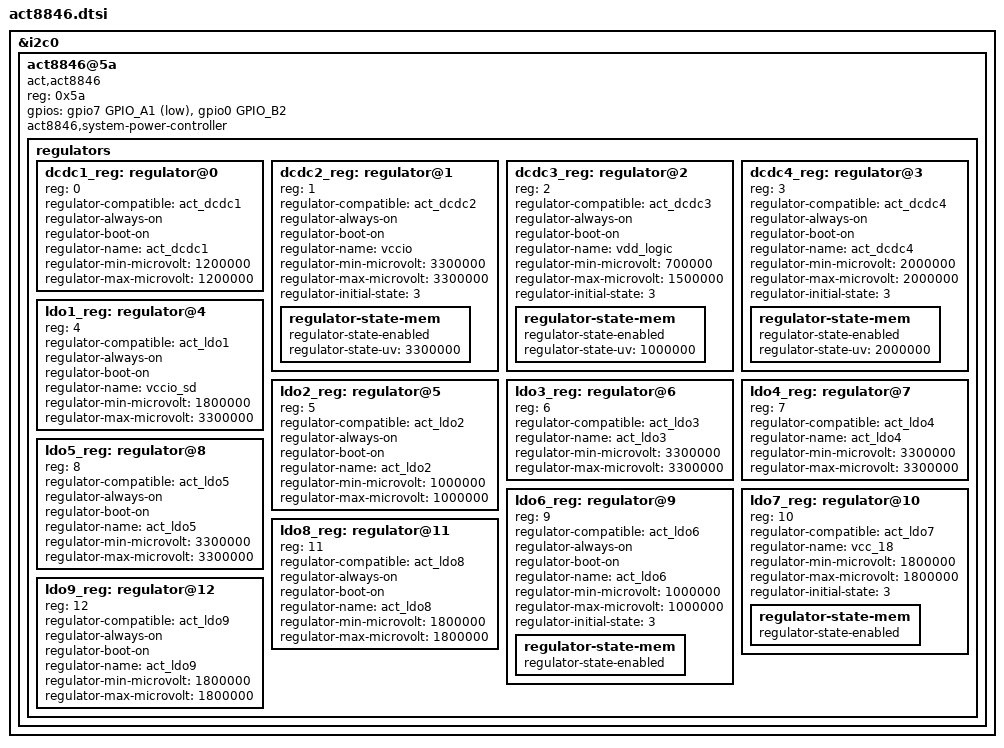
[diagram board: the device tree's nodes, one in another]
&i2c0 {
	act8846@5a {
		reg = <0x5a>;
		status = "okay";
		compatible = "act,act8846";
		gpios =<&gpio7 GPIO_A1 GPIO_ACTIVE_LOW>,<&gpio0 GPIO_B2 GPIO_ACTIVE_HIGH>;
		act8846,system-power-controller;
		regulators {
		#address-cells = <1>;
		#size-cells = <0>;

dcdc1_reg: regulator@0{
			   reg = <0>;
			   regulator-compatible= "act_dcdc1";
			   regulator-always-on;
			   regulator-boot-on;
			   regulator-name= "act_dcdc1";
			   regulator-min-microvolt = <1200000>;
			   regulator-max-microvolt = <1200000>;
		   };

dcdc2_reg: regulator@1 {
			   reg = <1>;
			   regulator-compatible = "act_dcdc2";
			   regulator-always-on;
			   regulator-boot-on;
			   regulator-name= "vccio";
			   regulator-min-microvolt = <3300000>;
			   regulator-max-microvolt = <3300000>;
			   regulator-initial-state = <3>;
			   regulator-state-mem {
				   regulator-state-enabled;
				   regulator-state-uv = <3300000>;
			   };
		   };

dcdc3_reg: regulator@2 {
			   reg = <2>;
			   regulator-compatible = "act_dcdc3";
			   regulator-always-on;
			   regulator-boot-on;
			   regulator-name= "vdd_logic";
			   regulator-min-microvolt = <700000>;
			   regulator-max-microvolt = <1500000>;
			   regulator-initial-state = <3>;
			   regulator-state-mem {
				   regulator-state-enabled;
				   regulator-state-uv = <1000000>;
			   };
		   };

dcdc4_reg: regulator@3 {
			   reg = <3>;
			   regulator-compatible = "act_dcdc4";
			   regulator-always-on;
			   regulator-boot-on;
			   regulator-name= "act_dcdc4";
			   regulator-min-microvolt = <2000000>;
			   regulator-max-microvolt = <2000000>;
			   regulator-initial-state = <3>;
			   regulator-state-mem {
				   regulator-state-enabled;
				   regulator-state-uv = <2000000>;
			   };
		   };

ldo1_reg: regulator@4 {
			  reg = <4>;
			  regulator-compatible= "act_ldo1";
			  regulator-always-on;
			  regulator-boot-on;
			  regulator-name= "vccio_sd";
			  regulator-min-microvolt = <1800000>;
			  regulator-max-microvolt = <3300000>;
		  };

ldo2_reg: regulator@5 {
			  reg = <5>;
			  regulator-compatible = "act_ldo2";
			  regulator-always-on;
			  regulator-boot-on;
			  regulator-name= "act_ldo2";
			  regulator-min-microvolt = <1000000>;
			  regulator-max-microvolt = <1000000>;
		  };

ldo3_reg: regulator@6 {
			  reg = <6>;
			  regulator-compatible = "act_ldo3";
			  /* regulator-always-on; */
			  /* regulator-boot-on; */
			  regulator-name= "act_ldo3";
			  regulator-min-microvolt = <3300000>;
			  regulator-max-microvolt = <3300000>;
		  };

ldo4_reg:regulator@7 {
			 reg = <7>;
			 regulator-compatible = "act_ldo4";
			 /* regulator-always-on; */
			 /*  regulator-boot-on; */
			 regulator-name= "act_ldo4";
			 regulator-min-microvolt = <3300000>;
			 regulator-max-microvolt = <3300000>;
		 };

ldo5_reg: regulator@8 {
			  reg = <8>;
			  regulator-compatible= "act_ldo5";
			  regulator-always-on;
			  regulator-boot-on;
			  regulator-name= "act_ldo5";
			  regulator-min-microvolt = <3300000>;
			  regulator-max-microvolt = <3300000>;
		  };

ldo6_reg: regulator@9 {
			  reg = <9>;
			  regulator-compatible = "act_ldo6";
			  regulator-always-on;
			  regulator-boot-on;
			  regulator-name= "act_ldo6";
			  regulator-min-microvolt = <1000000>;
			  regulator-max-microvolt = <1000000>;
			  regulator-initial-state = <3>;
			  regulator-state-mem {
				  regulator-state-enabled;
			  };
		  };

ldo7_reg: regulator@10 {
			  reg = <10>;
			  regulator-compatible = "act_ldo7";
			  /*regulator-always-on;*/
			  /* regulator-always-on; */
			  /*regulator-boot-on;*/
			  regulator-name= "vcc_18";
			  regulator-min-microvolt = <1800000>;
			  regulator-max-microvolt = <1800000>;
			  regulator-initial-state = <3>;
			  regulator-state-mem {
				  regulator-state-enabled;
			  };
		  };

ldo8_reg: regulator@11 {
			  reg = <11>;
			  regulator-compatible = "act_ldo8";
			  regulator-always-on;
			  regulator-boot-on;
			  regulator-name= "act_ldo8";
			  regulator-min-microvolt = <1800000>;
			  regulator-max-microvolt = <1800000>;
		  };

ldo9_reg: regulator@12 {
			  reg = <12>;
			  regulator-compatible = "act_ldo9";
			  regulator-always-on;
			  regulator-boot-on;
			  regulator-name= "act_ldo9";
			  regulator-min-microvolt = <1800000>;
			  regulator-max-microvolt = <1800000>;
		  };
		};
	};
};
